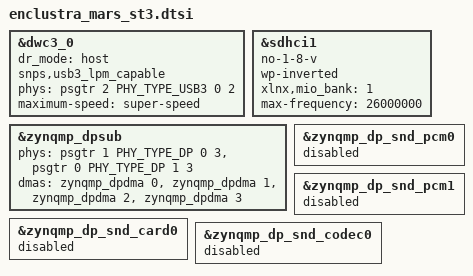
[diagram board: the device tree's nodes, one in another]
#include <dt-bindings/phy/phy.h>

&dwc3_0 {
	dr_mode = "host";
	snps,usb3_lpm_capable;
	phy-names = "usb3-phy";
	phys = <&psgtr 2 PHY_TYPE_USB3 0 2>;
	maximum-speed = "super-speed";
};

/* SD1 with level shifter */
&sdhci1 {
	no-1-8-v;	/* for 1.0 silicon */
	wp-inverted;
	xlnx,mio_bank = <1>;
	max-frequency = <26000000>;
};

&zynqmp_dpsub {
	phy-names = "dp-phy0", "dp-phy1";
	phys = <&psgtr 1 PHY_TYPE_DP 0 3>, <&psgtr 0 PHY_TYPE_DP 1 3>;
	dma-names = "vid0", "vid1", "vid2", "gfx0";
	dmas = <&zynqmp_dpdma 0>, <&zynqmp_dpdma 1>, <&zynqmp_dpdma 2>, <&zynqmp_dpdma 3>;
};

&zynqmp_dp_snd_pcm0 {
    status = "disabled";
};

&zynqmp_dp_snd_pcm1 {
    status = "disabled";
};

&zynqmp_dp_snd_card0 {
    status = "disabled";
};

&zynqmp_dp_snd_codec0 {
    status = "disabled";
};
